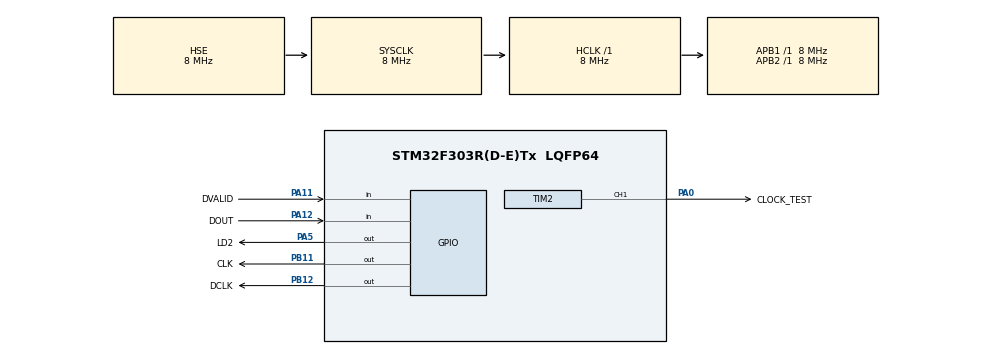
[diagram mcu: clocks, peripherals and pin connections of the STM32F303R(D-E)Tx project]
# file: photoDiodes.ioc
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Mcu.Family=STM32F3
Mcu.Name=STM32F303R(D-E)Tx
Mcu.Package=LQFP64
NVIC.PriorityGroup=NVIC_PRIORITYGROUP_4
PA0.GPIO_Label=CLOCK_TEST
PA0.GPIO_Speed=GPIO_SPEED_FREQ_HIGH
PA0.Signal=S_TIM2_CH1_ETR
PA11.GPIO_Label=DVALID
PA11.GPIO_PuPd=GPIO_PULLUP
PA11.Signal=GPIO_Input
PA12.GPIO_Label=DOUT
PA12.Signal=GPIO_Input
PA13.Mode=Serial_Wire
PA13.Signal=SYS_JTMS-SWDIO
PA14.Mode=Serial_Wire
PA14.Signal=SYS_JTCK-SWCLK
PA5.GPIO_Label=LD2
PA5.Signal=GPIO_Output
PB11.GPIO_Label=CLK
PB11.GPIO_Speed=GPIO_SPEED_FREQ_HIGH
PB11.PinState=GPIO_PIN_RESET
PB11.Signal=GPIO_Output
PB12.GPIO_Label=DCLK
PB12.GPIO_ModeDefaultOutputPP=GPIO_MODE_OUTPUT_PP
PB12.GPIO_Speed=GPIO_SPEED_FREQ_HIGH
PB12.PinState=GPIO_PIN_RESET
PB12.Signal=GPIO_Output
PF0-OSC_IN.Mode=HSE-External-Oscillator
PF0-OSC_IN.Signal=RCC_OSC_IN
PF1-OSC_OUT.Mode=HSE-External-Oscillator
PF1-OSC_OUT.Signal=RCC_OSC_OUT
ProjectManager.HeapSize=0x200
ProjectManager.StackSize=0x400
ProjectManager.TargetToolchain=Makefile
RCC.AHBFreq_Value=8000000
RCC.APB1Freq_Value=8000000
RCC.APB1TimFreq_Value=8000000
RCC.APB2Freq_Value=8000000
RCC.APB2TimFreq_Value=8000000
RCC.CortexFreq_Value=8000000
RCC.HCLKFreq_Value=8000000
RCC.HSE_VALUE=8000000
RCC.HSI_VALUE=8000000
RCC.LSE_VALUE=32768
RCC.PLLSourceVirtual=RCC_PLLSOURCE_HSE
RCC.SYSCLKFreq_VALUE=8000000
RCC.SYSCLKSourceVirtual=RCC_SYSCLKSOURCE_HSE
RCC.USBFreq_Value=16000000
SH.S_TIM2_CH1_ETR.0=TIM2_CH1,PWM Generation1 CH1
TIM2.Channel-PWM\ Generation1\ CH1=TIM_CHANNEL_1
TIM2.Period=1
TIM2.Prescaler=0
TIM2.Pulse-PWM\ Generation1\ CH1=1
board=custom

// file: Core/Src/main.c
/* USER CODE BEGIN Header */
/**
  ******************************************************************************
  * @file           : main.c
  * @brief          : Main program body
  ******************************************************************************
  * @attention
  *
  * <h2><center>&copy; Copyright (c) 2019 STMicroelectronics.
  * All rights reserved.</center></h2>
  *
  * This software component is licensed by ST under BSD 3-Clause license,
  * the "License"; You may not use this file except in compliance with the
  * License. You may obtain a copy of the License at:
  *                        opensource.org/licenses/BSD-3-Clause
  *
  ******************************************************************************
  */
/* USER CODE END Header */

#include "main.h"
#include "tim.h"
#include "gpio.h"

void SystemClock_Config(void);

int main(void)
{

  /* MCU Configuration--------------------------------------------------------*/

  /* Reset of all peripherals, Initializes the Flash interface and the Systick. */
  HAL_Init();

  /* Configure the system clock */
  SystemClock_Config();

  /* Initialize all configured peripherals */
  MX_GPIO_Init();
  MX_TIM2_Init();
  /* USER CODE BEGIN 2 */
  HAL_TIM_PWM_Start(&htim2, TIM_CHANNEL_1);
  /* USER CODE END 2 */

  /* Infinite loop */
  /* USER CODE BEGIN WHILE */
  while (1)
  {

    HAL_Delay(1000);
    HAL_GPIO_TogglePin(LD2_GPIO_Port, LD2_Pin);
    /* USER CODE END WHILE */

  }
}

void SystemClock_Config(void)
{
  RCC_OscInitTypeDef RCC_OscInitStruct = {0};
  RCC_ClkInitTypeDef RCC_ClkInitStruct = {0};
  RCC_PeriphCLKInitTypeDef PeriphClkInit = {0};

  /** Initializes the CPU, AHB and APB busses clocks
  */
  RCC_OscInitStruct.OscillatorType = RCC_OSCILLATORTYPE_HSE;
  RCC_OscInitStruct.HSEState = RCC_HSE_ON;
  RCC_OscInitStruct.HSIState = RCC_HSI_ON;
  RCC_OscInitStruct.PLL.PLLState = RCC_PLL_NONE;
  if (HAL_RCC_OscConfig(&RCC_OscInitStruct) != HAL_OK)
  {
    Error_Handler();
  }
  /** Initializes the CPU, AHB and APB busses clocks
  */
  RCC_ClkInitStruct.ClockType = RCC_CLOCKTYPE_HCLK|RCC_CLOCKTYPE_SYSCLK
                              |RCC_CLOCKTYPE_PCLK1|RCC_CLOCKTYPE_PCLK2;
  RCC_ClkInitStruct.SYSCLKSource = RCC_SYSCLKSOURCE_HSE;
  RCC_ClkInitStruct.AHBCLKDivider = RCC_SYSCLK_DIV1;
  RCC_ClkInitStruct.APB1CLKDivider = RCC_HCLK_DIV1;
  RCC_ClkInitStruct.APB2CLKDivider = RCC_HCLK_DIV1;

  if (HAL_RCC_ClockConfig(&RCC_ClkInitStruct, FLASH_LATENCY_0) != HAL_OK)
  {
    Error_Handler();
  }
  PeriphClkInit.PeriphClockSelection = RCC_PERIPHCLK_TIM2;
  PeriphClkInit.Tim2ClockSelection = RCC_TIM2CLK_HCLK;
  if (HAL_RCCEx_PeriphCLKConfig(&PeriphClkInit) != HAL_OK)
  {
    Error_Handler();
  }
}

void Error_Handler(void)
{
}

/************************ (C) COPYRIGHT STMicroelectronics *****END OF FILE****/
